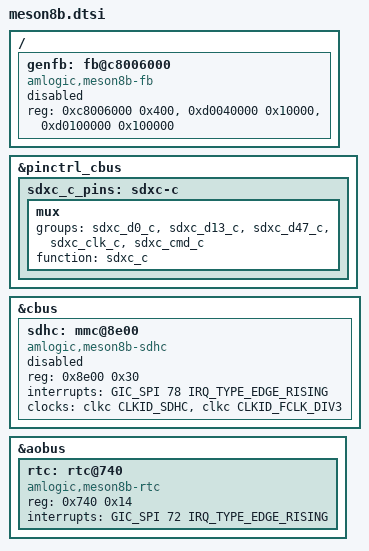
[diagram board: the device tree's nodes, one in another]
/* $NetBSD: meson8b.dtsi,v 1.5.6.3 2020/04/13 08:03:33 martin Exp $ */

/*-
 * Copyright (c) 2019 Jared McNeill <jmcneill@invisible.ca>
 * All rights reserved.
 *
 * Redistribution and use in source and binary forms, with or without
 * modification, are permitted provided that the following conditions
 * are met:
 * 1. Redistributions of source code must retain the above copyright
 *    notice, this list of conditions and the following disclaimer.
 * 2. Redistributions in binary form must reproduce the above copyright
 *    notice, this list of conditions and the following disclaimer in the
 *    documentation and/or other materials provided with the distribution.
 *
 * THIS SOFTWARE IS PROVIDED BY THE AUTHOR ``AS IS'' AND ANY EXPRESS OR
 * IMPLIED WARRANTIES, INCLUDING, BUT NOT LIMITED TO, THE IMPLIED WARRANTIES
 * OF MERCHANTABILITY AND FITNESS FOR A PARTICULAR PURPOSE ARE DISCLAIMED.
 * IN NO EVENT SHALL THE AUTHOR BE LIABLE FOR ANY DIRECT, INDIRECT,
 * INCIDENTAL, SPECIAL, EXEMPLARY, OR CONSEQUENTIAL DAMAGES (INCLUDING,
 * BUT NOT LIMITED TO, PROCUREMENT OF SUBSTITUTE GOODS OR SERVICES;
 * LOSS OF USE, DATA, OR PROFITS; OR BUSINESS INTERRUPTION) HOWEVER CAUSED
 * AND ON ANY THEORY OF LIABILITY, WHETHER IN CONTRACT, STRICT LIABILITY,
 * OR TORT (INCLUDING NEGLIGENCE OR OTHERWISE) ARISING IN ANY WAY
 * OUT OF THE USE OF THIS SOFTWARE, EVEN IF ADVISED OF THE POSSIBILITY OF
 * SUCH DAMAGE.
 */

/ {
	genfb: fb@c8006000 {
		compatible = "amlogic,meson8b-fb";
		reg = <0xc8006000 0x400>,	/* DMC */
		      <0xd0040000 0x10000>,	/* HDMI */
		      <0xd0100000 0x100000>;	/* VPU */
		status = "disabled";
	};
};

&pinctrl_cbus {
	sdxc_c_pins: sdxc-c {
		mux {
			groups = "sdxc_d0_c", "sdxc_d13_c", "sdxc_d47_c", "sdxc_clk_c", "sdxc_cmd_c";
			function = "sdxc_c";
		};
	};
};

&cbus {
	sdhc: mmc@8e00 {
		compatible = "amlogic,meson8b-sdhc";
		reg = <0x8e00 0x30>;
		interrupts = <GIC_SPI 78 IRQ_TYPE_EDGE_RISING>;
		clocks = <&clkc CLKID_SDHC>, <&clkc CLKID_FCLK_DIV3>;
		clock-names = "core", "clkin";
		#address-cells = <1>;
		#size-cells = <0>;
		status = "disabled";
	};
};

&aobus {
	rtc: rtc@740 {
		compatible = "amlogic,meson8b-rtc";
		reg = <0x740 0x14>;
		interrupts = <GIC_SPI 72 IRQ_TYPE_EDGE_RISING>;
	};
};
